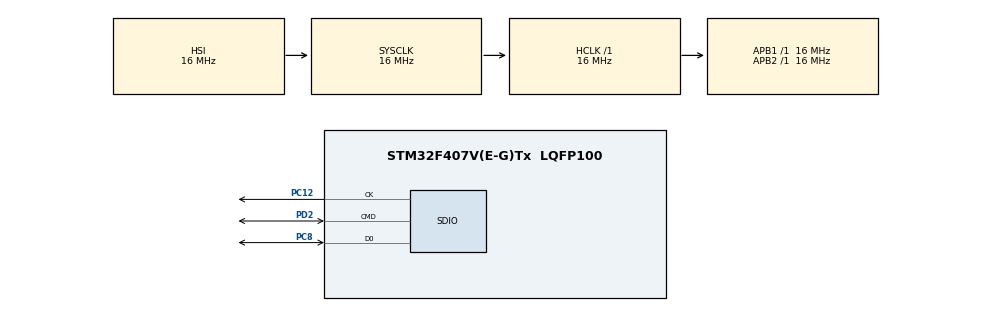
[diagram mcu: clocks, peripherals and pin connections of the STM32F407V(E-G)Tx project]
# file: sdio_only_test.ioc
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Dma.Request0=SDIO
Dma.SDIO.0.Direction=DMA_PERIPH_TO_MEMORY
Dma.SDIO.0.FIFOMode=DMA_FIFOMODE_ENABLE
Dma.SDIO.0.FIFOThreshold=DMA_FIFO_THRESHOLD_FULL
Dma.SDIO.0.Instance=DMA2_Stream3
Dma.SDIO.0.MemBurst=DMA_MBURST_INC4
Dma.SDIO.0.MemDataAlignment=DMA_MDATAALIGN_WORD
Dma.SDIO.0.MemInc=DMA_MINC_ENABLE
Dma.SDIO.0.Mode=DMA_PFCTRL
Dma.SDIO.0.PeriphBurst=DMA_PBURST_INC4
Dma.SDIO.0.PeriphDataAlignment=DMA_PDATAALIGN_WORD
Dma.SDIO.0.PeriphInc=DMA_PINC_DISABLE
Dma.SDIO.0.Priority=DMA_PRIORITY_LOW
Mcu.Family=STM32F4
Mcu.Name=STM32F407V(E-G)Tx
Mcu.Package=LQFP100
NVIC.DMA2_Stream3_IRQn=true\:0\:0\:false\:false\:true\:false\:true\:true
NVIC.PriorityGroup=NVIC_PRIORITYGROUP_4
NVIC.SDIO_IRQn=true\:0\:0\:false\:false\:true\:true\:true\:true
PA13.Mode=Serial_Wire
PA13.Signal=SYS_JTMS-SWDIO
PA14.Mode=Serial_Wire
PA14.Signal=SYS_JTCK-SWCLK
PC12.Mode=SD_1_bit
PC12.Signal=SDIO_CK
PC8.Mode=SD_1_bit
PC8.Signal=SDIO_D0
PD2.Mode=SD_1_bit
PD2.Signal=SDIO_CMD
PH0-OSC_IN.Mode=HSE-External-Oscillator
PH0-OSC_IN.Signal=RCC_OSC_IN
PH1-OSC_OUT.Mode=HSE-External-Oscillator
PH1-OSC_OUT.Signal=RCC_OSC_OUT
ProjectManager.HeapSize=0x200
ProjectManager.StackSize=0x400
ProjectManager.TargetToolchain=STM32CubeIDE
RCC.48MHZClocksFreq_Value=20000000
RCC.AHBFreq_Value=16000000
RCC.APB1Freq_Value=16000000
RCC.APB2Freq_Value=16000000
RCC.CortexFreq_Value=16000000
RCC.HSE_VALUE=25000000
RCC.HSI_VALUE=16000000
RCC.LSE_VALUE=32768
RCC.PLLQ=15
RCC.PLLSourceVirtual=RCC_PLLSOURCE_HSE
RCC.SYSCLKFreq_VALUE=16000000
RCC.VCOOutputFreq_Value=300000000
VP_FATFS_VS_SDIO.Mode=SDIO
board=custom

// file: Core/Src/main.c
/* USER CODE BEGIN Header */
/**
  ******************************************************************************
  * @file           : main.c
  * @brief          : Main program body
  ******************************************************************************
  * @attention
  *
  * Copyright (c) 2024 STMicroelectronics.
  * All rights reserved.
  *
  * This software is licensed under terms that can be found in the LICENSE file
  * in the root directory of this software component.
  * If no LICENSE file comes with this software, it is provided AS-IS.
  *
  ******************************************************************************
  */
/* USER CODE END Header */
#include "main.h"
#include "fatfs.h"

SD_HandleTypeDef hsd;
DMA_HandleTypeDef hdma_sdio;

void SystemClock_Config(void);
static void MX_GPIO_Init(void);
static void MX_DMA_Init(void);
static void MX_SDIO_SD_Init(void);

int main(void)
{

  /* MCU Configuration--------------------------------------------------------*/

  /* Reset of all peripherals, Initializes the Flash interface and the Systick. */
  HAL_Init();

  /* Configure the system clock */
  SystemClock_Config();

  /* Initialize all configured peripherals */
  MX_GPIO_Init();
  MX_DMA_Init();
  MX_SDIO_SD_Init();
  MX_FATFS_Init();
  /* USER CODE BEGIN 2 */
  HAL_SD_Init(&hsd);

  FATFS fileSystem;
   FIL testFile;
   DIR testDir;
   uint8_t testBuffer[16] = "SD write success";
   UINT testBytes;
   FRESULT res;
   if(f_mount(&fileSystem, SDPath, 1) == FR_OK)
   {
     uint8_t path[14] = "testfile.jpeg";
     path[13] = '\0';
     res = f_open(&testFile, (char*)path, FA_WRITE | FA_CREATE_ALWAYS);
     res = f_write(&testFile, testBuffer, 16, &testBytes);
     res = f_close(&testFile);
     f_mkdir("testDir");
   }
  /* USER CODE END 2 */

  /* Infinite loop */
  while (1)
  {

  }
}

void SystemClock_Config(void)
{
  RCC_OscInitTypeDef RCC_OscInitStruct = {0};
  RCC_ClkInitTypeDef RCC_ClkInitStruct = {0};

  /** Configure the main internal regulator output voltage
  */
  __HAL_RCC_PWR_CLK_ENABLE();
  __HAL_PWR_VOLTAGESCALING_CONFIG(PWR_REGULATOR_VOLTAGE_SCALE1);

  /** Initializes the RCC Oscillators according to the specified parameters
  * in the RCC_OscInitTypeDef structure.
  */
  RCC_OscInitStruct.OscillatorType = RCC_OSCILLATORTYPE_HSI|RCC_OSCILLATORTYPE_HSE;
  RCC_OscInitStruct.HSEState = RCC_HSE_ON;
  RCC_OscInitStruct.HSIState = RCC_HSI_ON;
  RCC_OscInitStruct.HSICalibrationValue = RCC_HSICALIBRATION_DEFAULT;
  RCC_OscInitStruct.PLL.PLLState = RCC_PLL_ON;
  RCC_OscInitStruct.PLL.PLLSource = RCC_PLLSOURCE_HSE;
  RCC_OscInitStruct.PLL.PLLM = 16;
  RCC_OscInitStruct.PLL.PLLN = 192;
  RCC_OscInitStruct.PLL.PLLP = RCC_PLLP_DIV2;
  RCC_OscInitStruct.PLL.PLLQ = 15;
  if (HAL_RCC_OscConfig(&RCC_OscInitStruct) != HAL_OK)
  {
    Error_Handler();
  }

  /** Initializes the CPU, AHB and APB buses clocks
  */
  RCC_ClkInitStruct.ClockType = RCC_CLOCKTYPE_HCLK|RCC_CLOCKTYPE_SYSCLK
                              |RCC_CLOCKTYPE_PCLK1|RCC_CLOCKTYPE_PCLK2;
  RCC_ClkInitStruct.SYSCLKSource = RCC_SYSCLKSOURCE_HSI;
  RCC_ClkInitStruct.AHBCLKDivider = RCC_SYSCLK_DIV1;
  RCC_ClkInitStruct.APB1CLKDivider = RCC_HCLK_DIV1;
  RCC_ClkInitStruct.APB2CLKDivider = RCC_HCLK_DIV1;

  if (HAL_RCC_ClockConfig(&RCC_ClkInitStruct, FLASH_LATENCY_0) != HAL_OK)
  {
    Error_Handler();
  }
}

static void MX_SDIO_SD_Init(void)
{

  hsd.Instance = SDIO;
  hsd.Init.ClockEdge = SDIO_CLOCK_EDGE_RISING;
  hsd.Init.ClockBypass = SDIO_CLOCK_BYPASS_DISABLE;
  hsd.Init.ClockPowerSave = SDIO_CLOCK_POWER_SAVE_DISABLE;
  hsd.Init.BusWide = SDIO_BUS_WIDE_1B;
  hsd.Init.HardwareFlowControl = SDIO_HARDWARE_FLOW_CONTROL_DISABLE;
  hsd.Init.ClockDiv = 0;

}

static void MX_DMA_Init(void)
{

  /* DMA controller clock enable */
  __HAL_RCC_DMA2_CLK_ENABLE();

  /* DMA interrupt init */
  /* DMA2_Stream3_IRQn interrupt configuration */
  HAL_NVIC_SetPriority(DMA2_Stream3_IRQn, 0, 0);
  HAL_NVIC_EnableIRQ(DMA2_Stream3_IRQn);

}

static void MX_GPIO_Init(void)
{

  /* GPIO Ports Clock Enable */
  __HAL_RCC_GPIOH_CLK_ENABLE();
  __HAL_RCC_GPIOC_CLK_ENABLE();
  __HAL_RCC_GPIOA_CLK_ENABLE();
  __HAL_RCC_GPIOD_CLK_ENABLE();

}

void Error_Handler(void)
{
  __disable_irq();
  while (1)
  {
  }
}
